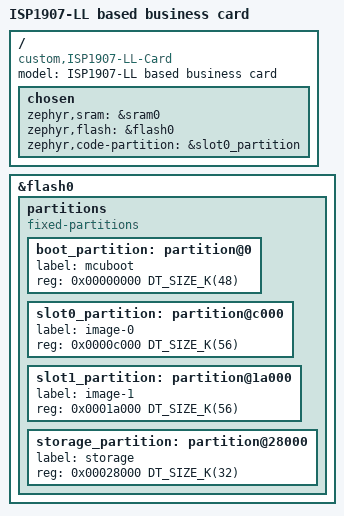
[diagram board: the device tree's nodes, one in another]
/dts-v1/;
#include <nordic/nrf52811_qfaa.dtsi>
#include "ISP1907-LL_Card-pinctrl.dtsi"

/ {
	model = "ISP1907-LL based business card";
	compatible = "custom,ISP1907-LL-Card";

	chosen {
		zephyr,sram = &sram0;
		zephyr,flash = &flash0;
		zephyr,code-partition = &slot0_partition;
	};
};

&flash0 {
	partitions {
		compatible = "fixed-partitions";
		#address-cells = <1>;
		#size-cells = <1>;

		boot_partition: partition@0 {
			label = "mcuboot";
			reg = <0x00000000 DT_SIZE_K(48)>;
		};

		slot0_partition: partition@c000 {
			label = "image-0";
			reg = <0x0000c000 DT_SIZE_K(56)>;
		};

		slot1_partition: partition@1a000 {
			label = "image-1";
			reg = <0x0001a000 DT_SIZE_K(56)>;
		};

		storage_partition: partition@28000 {
			label = "storage";
			reg = <0x00028000 DT_SIZE_K(32)>;
		};
	};
};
